AUTOSAR XML (schema 00046)
package /MyDataTypes
  base type My_uint8: category=FIXED_LENGTH, base-type-size=8, base-type-encoding=NONE, native-declaration=unsigned char
  impl type u8_t: category=VALUE, base-type=My_uint8, range phys 0..255, raw 0..255
package /Interfaces
  sender receiver interface SRI_DoorState
    data DoorState: type=u8_t
  client server interface CSIF_LedState
    operation SetLedState: possible-error=[Error_Not_OK, Error_OK]
      arg LedState_IN: type=u8_t, direction=IN
    error Error_Not_OK: error-code=1
    error Error_OK: error-code=0
package /SWCs
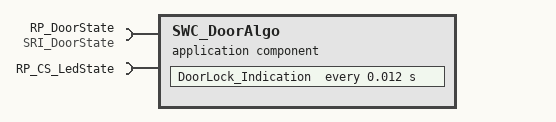
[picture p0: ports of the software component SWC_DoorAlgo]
  application sw component type SWC_DoorAlgo
    require port RP_DoorState: required-interface=SRI_DoorState
    require port RP_CS_LedState: client-server-annotation=CSIF_LedState
    behavior IB_SWC_DoorAlgo
      timing event TE_12ms: start-on-event=DoorLock_Indication, period=0.012
      runnable DoorLock_Indication: symbol=DoorLock_Indication_Runnable
        data-read-access:
          access DoorState_Value: accessed-variable=RP_DoorState.DoorState
        sync call ServerCall: operation=RP_CS_LedState.SetLedState
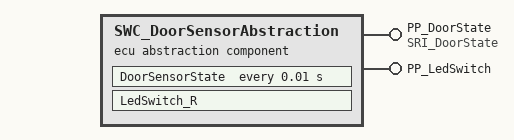
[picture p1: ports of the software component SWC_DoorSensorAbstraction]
  ecu abstraction sw component type SWC_DoorSensorAbstraction
    provide port PP_DoorState: provided-interface=SRI_DoorState
    provide port PP_LedSwitch: client-server-annotation=CSIF_LedState
    behavior IB_SWC_DoorSensorAbstraction
      timing event TE_10ms: start-on-event=DoorSensorState, period=0.01
      operation invoked event OPIE: start-on-event=LedSwitch_R, operation=PP_LedSwitch.SetLedState
      runnable DoorSensorState: symbol=GetDoorState_Runnable
        data-write-access:
          access DoorState_val: accessed-variable=PP_DoorState.DoorState
      runnable LedSwitch_R: symbol=Led_Switch_Runnable
package /Composition
  composition sw component type Compsit_DoorLock_SWC
    component CompsitSWC_DoorSensorAbstraction: type=SWC_DoorSensorAbstraction
    component CompsitSWC_DoorAlgo: type=SWC_DoorAlgo
    connect CompsitSWC_DoorSensorAbstraction.PP_DoorState -> CompsitSWC_DoorAlgo.RP_DoorState
    connect CompsitSWC_DoorSensorAbstraction.PP_LedSwitch -> CompsitSWC_DoorAlgo.RP_CS_LedState
